# EFM32PG22C200F256IM32 register map
Vendor: Silicon Labs; Series: EFM32; File version: C
Registers are 32-bit, read-write, reset 0x0 unless marked. A register's access mark holds for its fields unless they carry their own. Offsets are from the block's base; [hi:lo] are bit positions; 'fields as' and 'values as' point back to an identical list.

## HFXO0_S — HFXO0_S Registers
Base 0x4000C000
Same registers: HFXO0_NS 0x5000C000
0x00 IPVERSION ro reset 0x2
  [31:0] IPVERSION — IP Version ID
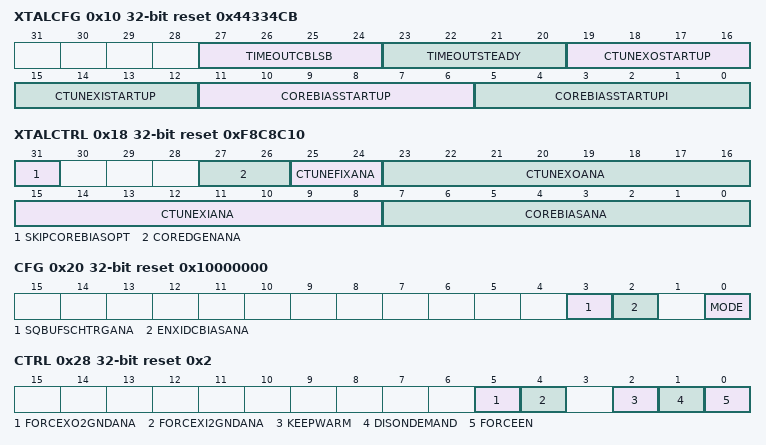
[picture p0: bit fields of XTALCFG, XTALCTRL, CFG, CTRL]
0x10 XTALCFG reset 0x44334CB
  [27:24] TIMEOUTCBLSB — Core Bias LSB Change Timeout
    0=T8US (The core bias LSB change timeout is set to 8 us minimum. The maximum can be +40%.); 1=T20US (The core bias LSB change timeout is set to 20 us minimum. The maximum can be +40%.); 2=T41US (The core bias LSB change timeout is set to 41 us minimum. The maximum can be +40%.); 3=T62US (The core bias LSB change timeout is set to 62 us minimum. The maximum can be +40%.); 4=T83US (The core bias LSB change timeout is set to 83 us minimum. The maximum can be +40%.); 5=T104US (The core bias LSB change timeout is set to 104 us minimum. The maximum can be +40%.); 6=T125US (The core bias LSB change timeout is set to 125 us minimum. The maximum can be +40%.); 7=T166US (The core bias LSB change timeout is set to 166 us minimum. The maximum can be +40%.); 8=T208US (The core bias LSB change timeout is set to 208 us minimum. The maximum can be +40%.); 9=T250US (The core bias LSB change timeout is set to 250 us minimum. The maximum can be +40%.); 10=T333US (The core bias LSB change timeout is set to 333 us minimum. The maximum can be +40%.); 11=T416US (The core bias LSB change timeout is set to 416 us minimum. The maximum can be +40%.); 12=T833US (The core bias LSB change timeout is set to 833 us minimum. The maximum can be +40%.); 13=T1250US (The core bias LSB change timeout is set to 1250 us minimum. The maximum can be +40%.); 14=T2083US (The core bias LSB change timeout is set to 2083 us minimum. The maximum can be +40%.); 15=T3750US (The core bias LSB change timeout is set to 3750 us minimum. The maximum can be +40%.)
  [23:20] TIMEOUTSTEADY — Steady State Timeout
    0=T16US (The steady state timeout is set to 16 us minimum. The maximum can be +40%.); 1=T41US (The steady state timeout is set to 41 us minimum. The maximum can be +40%.); 2=T83US (The steady state timeout is set to 83 us minimum. The maximum can be +40%.); 3=T125US (The steady state timeout is set to 125 us minimum. The maximum can be +40%.); 4=T166US (The steady state timeout is set to 166 us minimum. The maximum can be +40%.); 5=T208US (The steady state timeout is set to 208 us minimum. The maximum can be +40%.); 6=T250US (The steady state timeout is set to 250 us minimum. The maximum can be +40%.); 7=T333US (The steady state timeout is set to 333 us minimum. The maximum can be +40%.); 8=T416US (The steady state timeout is set to 416 us minimum. The maximum can be +40%.); 9=T500US (The steady state timeout is set to 500 us minimum. The maximum can be +40%.); 10=T666US (The steady state timeout is set to 666 us minimum. The maximum can be +40%.); 11=T833US (The steady state timeout is set to 833 us minimum. The maximum can be +40%.); 12=T1666US (The steady state timeout is set to 1666 us minimum. The maximum can be +40%.); 13=T2500US (The steady state timeout is set to 2500 us minimum. The maximum can be +40%.); 14=T4166US (The steady state timeout is set to 4166 us minimum. The maximum can be +40%.); 15=T7500US (The steady state timeout is set to 7500 us minimum. The maximum can be +40%.)
  [19:16] CTUNEXOSTARTUP — Startup Tuning Capacitance on XO
  [15:12] CTUNEXISTARTUP — Startup Tuning Capacitance on XI
  [11:6] COREBIASSTARTUP — Startup Core Bias Current
  [5:0] COREBIASSTARTUPI — Intermediate Startup Core Bias Current
0x18 XTALCTRL reset 0xF8C8C10
  [31] SKIPCOREBIASOPT — Skip Core Bias Optimization
  [27:26] COREDGENANA — Core Degeneration
    0=NONE (Do not apply core degeneration resistence); 1=DGEN33 (Apply 33 ohm core degeneration resistence); 2=DGEN50 (Apply 50 ohm core degeneration resistence); 3=DGEN100 (Apply 100 ohm core degeneration resistence)
  [25:24] CTUNEFIXANA — Fixed Tuning Capacitance
    0=NONE (Remove fixed capacitance on XI and XO nodes); 1=XI (Adds fixed capacitance on XI node); 2=XO (Adds fixed capacitance on XO node); 3=BOTH (Adds fixed capacitance on both XI and XO nodes)
  [23:16] CTUNEXOANA — Tuning Capacitance on XO
  [15:8] CTUNEXIANA — Tuning Capacitance on XI
  [7:0] COREBIASANA — Core Bias Current
0x20 CFG reset 0x10000000
  [3] SQBUFSCHTRGANA — Squaring Buffer Schmitt Trigger
    0=DISABLE (Squaring buffer schmitt trigger is disabled); 1=ENABLE (Squaring buffer schmitt trigger is enabled)
  [2] ENXIDCBIASANA — Enable XI Internal DC Bias
  [0] MODE — Crystal Oscillator Mode
    0=XTAL (crystal oscillator); 1=EXTCLK (external sinusoidal clock can be supplied on XI pin.)
0x28 CTRL reset 0x2
  [5] FORCEXO2GNDANA — Force XO Pin to Ground
    0=DISABLE (Disabled (not pulled)); 1=ENABLE (Enabled (pulled))
  [4] FORCEXI2GNDANA — Force XI Pin to Ground
    values as FORCEXO2GNDANA
  [2] KEEPWARM
  [1] DISONDEMAND — Disable On-demand Mode
  [0] FORCEEN — Force Enable
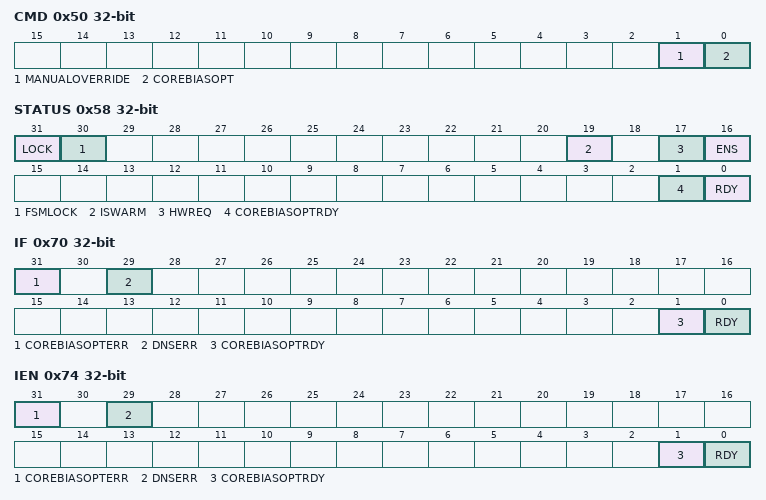
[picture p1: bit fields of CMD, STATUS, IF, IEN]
0x50 CMD wo
  [1] MANUALOVERRIDE
  [0] COREBIASOPT — Core Bias Optimizaton
0x58 STATUS ro
  [31] LOCK — Configuration Lock Status
    0=UNLOCKED (Configuration lock is unlocked); 1=LOCKED (Configuration lock is locked)
  [30] FSMLOCK — FSM Lock Status
    0=UNLOCKED (FSM lock is unlocked); 1=LOCKED (FSM lock is locked)
  [19] ISWARM — Oscillator Is Kept Warm
  [17] HWREQ — Oscillator Requested by Hardware
  [16] ENS — Enabled Status
  [1] COREBIASOPTRDY — Core Bias Optimization Ready
  [0] RDY — Ready Status
0x70 IF
  [31] COREBIASOPTERR — Core Bias Optimization Error Interrupt
  [29] DNSERR — Did Not Start Error Interrupt
  [1] COREBIASOPTRDY — Core Bias Optimization Ready Interrupt
  [0] RDY — Ready Interrupt
0x74 IEN
  fields as IF
0x80 LOCK wo reset 0x580E
  [15:0] LOCKKEY — Configuration Lock Key
    0x580E=UNLOCK (Write this value to unlock)
